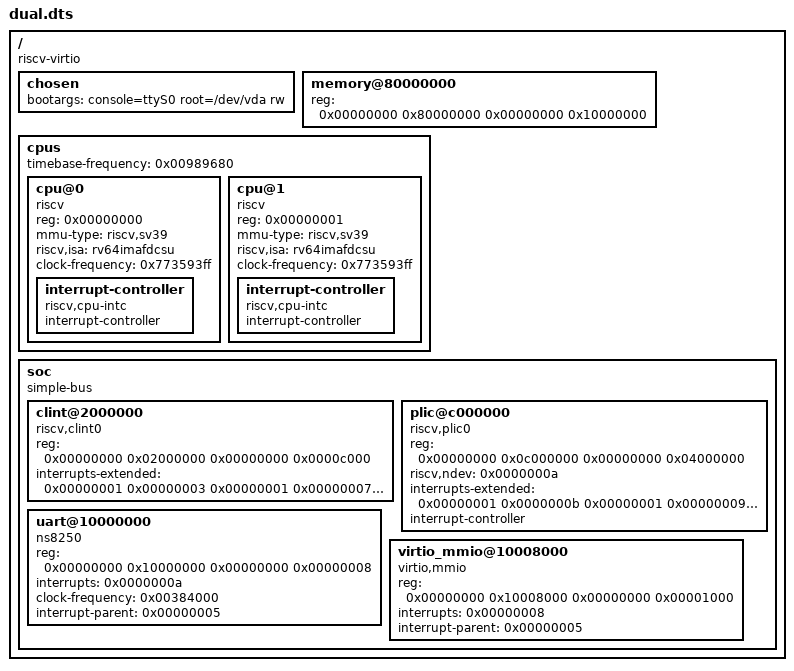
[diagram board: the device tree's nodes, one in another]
/dts-v1/;
// version:		17
// last_comp_version:	16
// boot_cpuid_phys:	0x0

/ {
    #address-cells = <0x00000002>;
    #size-cells = <0x00000002>;
    compatible = "riscv-virtio";
    chosen {
        bootargs = "console=ttyS0 root=/dev/vda rw";
    };
    memory@80000000 {
        device_type = "memory";
        reg = <0x00000000 0x80000000 0x00000000 0x10000000>;
    };
    cpus {
        #address-cells = <0x00000001>;
        #size-cells = <0x00000000>;
        timebase-frequency = <0x00989680>;
        cpu@0 {
            device_type = "cpu";
            reg = <0x00000000>;
            mmu-type = "riscv,sv39";
            status = "okay";
            riscv,isa = "rv64imafdcsu";
            compatible = "riscv";
            clock-frequency = <0x773593ff>;
            phandle = <0x00000002>;
            interrupt-controller {
                #interrupt-cells = <0x00000001>;
                interrupt-controller;
                compatible = "riscv,cpu-intc";
                phandle = <0x00000001>;
            };
        };
        cpu@1 {
            device_type = "cpu";
            reg = <0x00000001>;
            mmu-type = "riscv,sv39";
            status = "okay";
            riscv,isa = "rv64imafdcsu";
            compatible = "riscv";
            clock-frequency = <0x773593ff>;
            phandle = <0x00000004>;
            interrupt-controller {
                #interrupt-cells = <0x00000001>;
                interrupt-controller;
                compatible = "riscv,cpu-intc";
                phandle = <0x00000003>;
            };
        };
    };
    soc {
        #address-cells = <0x00000002>;
        #size-cells = <0x00000002>;
        ranges;
        compatible = "simple-bus";
        clint@2000000 {
            reg = <0x00000000 0x02000000 0x00000000 0x0000c000>;
            interrupts-extended = <0x00000001 0x00000003 0x00000001 0x00000007 0x00000003 0x00000003 0x00000003 0x00000007>;
            compatible = "riscv,clint0";
        };
        plic@c000000 {
            reg = <0x00000000 0x0c000000 0x00000000 0x04000000>;
            #address-cells = <0x00000000>;
            #interrupt-cells = <0x00000001>;
            phandle = <0x00000005>;
            riscv,ndev = <0x0000000a>;
            interrupts-extended = <0x00000001 0x0000000b 0x00000001 0x00000009 0x00000003 0x0000000b 0x00000003 0x00000009>;
            interrupt-controller;
            compatible = "riscv,plic0";
        };
        uart@10000000 {
            reg = <0x00000000 0x10000000 0x00000000 0x00000008>;
            interrupts = <0x0000000a>;
            clock-frequency = <0x00384000>;
            interrupt-parent = <0x00000005>;
            compatible = "ns8250";
        };
        virtio_mmio@10008000 {
            reg = <0x00000000 0x10008000 0x00000000 0x00001000>;
            interrupts = <0x00000008>;
            interrupt-parent = <0x00000005>;
            compatible = "virtio,mmio";
        };
    };
};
